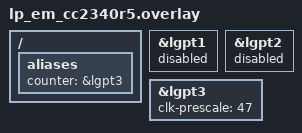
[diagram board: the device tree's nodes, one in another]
/*
 * Copyright (c) 2025 Texas Instruments Incorporated
 * Copyright (c) 2025 BayLibre, SAS
 *
 * SPDX-License-Identifier: Apache-2.0
 */

/ {
	aliases {
		counter = &lgpt3;
	};
};

/* Disable 16-bit timers - they can't handle large test values */
&lgpt1 {
	status = "disabled";
};

&lgpt2 {
	status = "disabled";
};

/* Use lgpt3 (24-bit) for better test coverage with longer timeouts */
&lgpt3 {
	clk-prescale = <47>;  /* 48MHz / 48 = 1MHz, 1us per tick */
	status = "okay";
};
